# STM32WL5x_CM0P register map
File version: 1.5
CPU: CM0 r0p1, little endian, MPU, no FPU, 4 interrupt priority bits
Registers are 32-bit, read-write, reset 0x0 unless marked. A register's access mark holds for its fields unless they carry their own. Offsets are from the block's base; [hi:lo] are bit positions; {n}, {i} and the like mark numbered series.

## PWR — Power control
Base 0x58000400
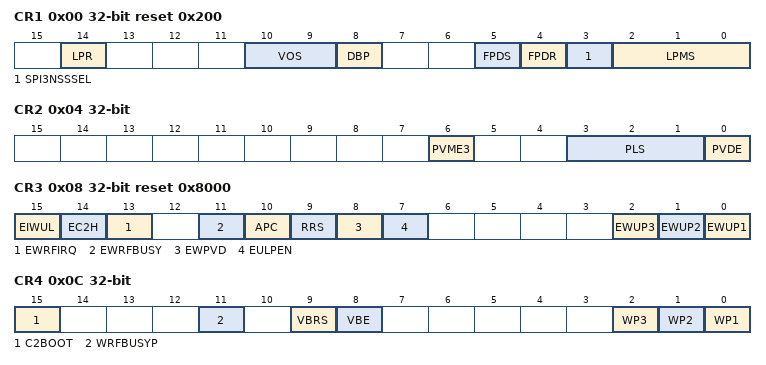
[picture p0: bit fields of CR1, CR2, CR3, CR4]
0x00 CR1 reset 0x200 — Power control register 1
  [14] LPR — Low-power run
  [10:9] VOS — Voltage scaling range selection
  [8] DBP — Disable backup domain write protection
  [5] FPDS — Flash memory power down mode during LPSleep for CPU1
  [4] FPDR — Flash memory power down mode during LPRun for CPU1
  [3] SPI3NSSSEL — SPI3 NSS source select
  [2:0] LPMS — Low-power mode selection for CPU1
0x04 CR2 — Power control register 2
  [6] PVME3 — Peripheral voltage monitoring 3 enable: VDDA vs. 1.62V
  [3:1] PLS — Power voltage detector level selection.
  [0] PVDE — Power voltage detector enable
0x08 CR3 reset 0x8000 — Power control register 3
  [15] EIWUL — Enable internal wakeup line for CPU1
  [14] EC2H — nable CPU2 Hold interrupt for CPU1
  [13] EWRFIRQ — akeup for CPU1
  [11] EWRFBUSY — Enable Radio BUSY Wakeup from Standby for CPU1
  [10] APC — Apply pull-up and pull-down configuration from CPU1
  [9] RRS — SRAM2 retention in Standby mode
  [8] EWPVD — Enable wakeup PVD for CPU1
  [7] EULPEN — Ultra-low-power enable
  [2] EWUP3 — Enable Wakeup pin WKUP3 for CPU1
  [1] EWUP2 — Enable Wakeup pin WKUP2 for CPU1
  [0] EWUP1 — Enable Wakeup pin WKUP1 for CPU1
0x0C CR4 — Power control register 4
  [15] C2BOOT — oot CPU2 after reset or wakeup from Stop or Standby modes.
  [11] WRFBUSYP — Wakeup Radio BUSY polarity
  [9] VBRS — VBAT battery charging resistor selection
  [8] VBE — VBAT battery charging enable
  [2] WP3 — Wakeup pin WKUP3 polarity
  [1] WP2 — Wakeup pin WKUP2 polarity
  [0] WP1 — Wakeup pin WKUP1 polarity
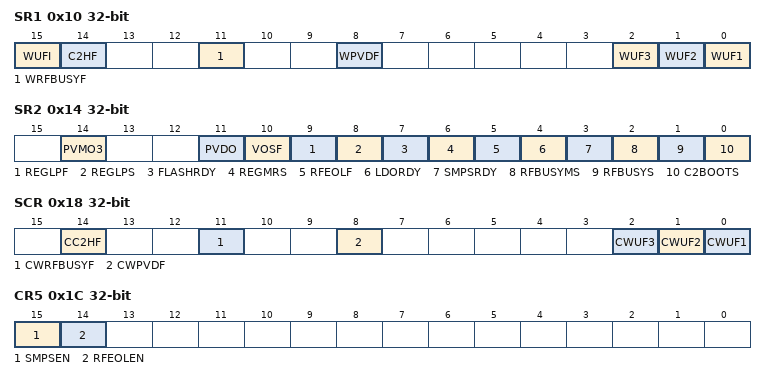
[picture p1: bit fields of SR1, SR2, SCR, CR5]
0x10 SR1 ro — Power status register 1
  [15] WUFI — Internal wakeup interrupt flag
  [14] C2HF — PU2 Hold interrupt flag
  [11] WRFBUSYF — Radio BUSY wakeup flag
  [8] WPVDF — Wakeup PVD flag
  [2] WUF3 — Wakeup flag 3
  [1] WUF2 — Wakeup flag 2
  [0] WUF1 — Wakeup flag 1
0x14 SR2 ro — Power status register 2
  [14] PVMO3 — Peripheral voltage monitoring output: VDDA vs. 1.62 V
  [11] PVDO — Power voltage detector output
  [10] VOSF — Voltage scaling flag
  [9] REGLPF — regulator1 low power flag
  [8] REGLPS — regulator1 started
  [7] FLASHRDY — Flash ready
  [6] REGMRS — regulator2 low power flag
  [5] RFEOLF — Radio end of life flag
  [4] LDORDY — LDO ready flag
  [3] SMPSRDY — SMPS ready flag
  [2] RFBUSYMS — Radio BUSY masked signal status
  [1] RFBUSYS — Radio BUSY signal status
  [0] C2BOOTS — PU2 boot/wakeup request source information
0x18 SCR wo — Power status clear register
  [14] CC2HF — lear CPU2 Hold interrupt flag
  [11] CWRFBUSYF — Clear wakeup Radio BUSY flag
  [8] CWPVDF — Clear wakeup PVD interrupt flag
  [2] CWUF3 — Clear wakeup flag 3
  [1] CWUF2 — Clear wakeup flag 2
  [0] CWUF1 — Clear wakeup flag 1
0x1C CR5 — Power control register 5
  [15] SMPSEN — Enable SMPS Step Down converter SMPS mode enabled.
  [14] RFEOLEN — Enable Radio End Of Life detector enabled
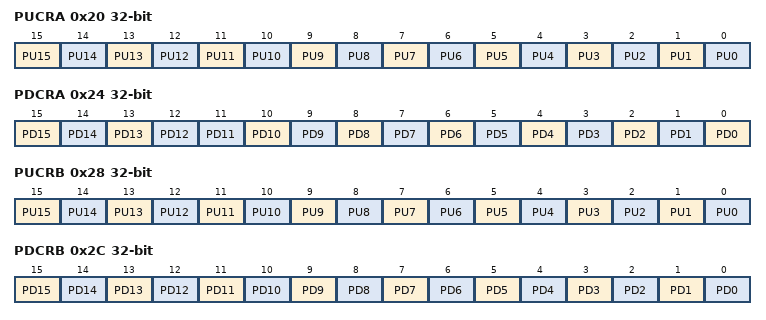
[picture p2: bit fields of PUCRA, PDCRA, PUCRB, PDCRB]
0x20 PUCRA — Power Port A pull-up control register
  [15] PU15 — Port PA15 pull-up
  [14] PU14
  [13] PU13 — Port PA[y] pull-up bit y (y=0 to 13)
  [n] PU{n} (n=0..12)
0x24 PDCRA — Power Port A pull-down control register
  [15] PD15
  [14] PD14 — ull-down
  [13] PD13
  [12] PD12 — Port PA[y] pull-down (y=0 to 12)
  [n] PD{n} (n=0..11)
0x28 PUCRB — Power Port B pull-up control register
  [15] PU15 — Port PB[y] pull-up (y=0 to 15)
  [n] PU{n} (n=0..14)
0x2C PDCRB — Power Port B pull-down control register
  [15] PD15 — Port PB[y] pull-down (y=5 to 15)
  [n] PD{n} (n=4..14)
  [3] PD3 — Port PB[y] pull-down (y=0 to 3)
  [2] PD2
  [1] PD1
  [0] PD0
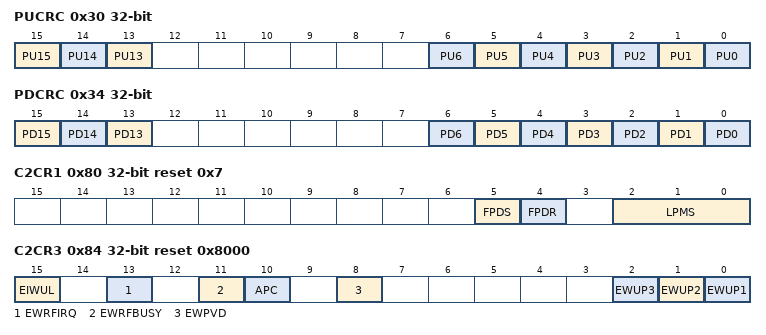
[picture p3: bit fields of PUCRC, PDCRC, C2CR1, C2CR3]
0x30 PUCRC — Power Port C pull-up control register
  [15] PU15 — Port PC[y] pull-up (y=13 to 15)
  [14] PU14
  [13] PU13
  [n] PU{n} (n=0..6)
0x34 PDCRC — Power Port C pull-down control register
  [15] PD15 — Port PC[y] pull-down (y=13 to 15)
  [14] PD14
  [13] PD13
  [n] PD{n} (n=0..6)
0x58 PUCRH — Power Port H pull-up control register
  [3] PU3 — ull-up
0x5C PDCRH — Power Port H pull-down control register
  [3] PD3 — ull-down
0x80 C2CR1 reset 0x7 — Power CPU2 control register 1 [dual core device only]
  [5] FPDS — Flash memory power down mode during LPSleep for CPU2
  [4] FPDR — Flash memory power down mode during LPRun for CPU2
  [2:0] LPMS — Low-power mode selection for CPU2
0x84 C2CR3 reset 0x8000 — Power CPU2 control register 3 [dual core device only]
  [15] EIWUL — Enable internal wakeup line for CPU2
  [13] EWRFIRQ — akeup for CPU2
  [11] EWRFBUSY
  [10] APC — Apply pull-up and pull-down configuration for CPU2
  [8] EWPVD — Enable wakeup PVD for CPU2
  [2] EWUP3 — Enable Wakeup pin WKUP3 for CPU2
  [1] EWUP2 — Enable Wakeup pin WKUP2 for CPU2
  [0] EWUP1 — Enable Wakeup pin WKUP1 for CPU2
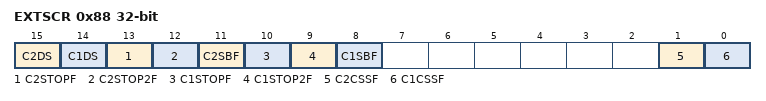
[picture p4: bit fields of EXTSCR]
0x88 EXTSCR access per field — Power extended status and status clear register
  [15] C2DS ro — PU2 deepsleep mode
  [14] C1DS ro — CPU1 deepsleep mode
  [13] C2STOPF ro — ystem Stop0, 1 flag for CPU2. (All core states retained)
  [12] C2STOP2F ro — ystem Stop2 flag for CPU2. (partial core states retained)
  [11] C2SBF ro — ystem Standby flag for CPU2. (no core states retained)
  [10] C1STOPF ro — System Stop0, 1 flag for CPU1. (All core states retained)
  [9] C1STOP2F ro — System Stop2 flag for CPU1. (partial core states retained)
  [8] C1SBF ro — System Standby flag for CPU1. (no core states retained)
  [1] C2CSSF wo — lear CPU2 Stop Standby flags
  [0] C1CSSF wo — Clear CPU1 Stop Standby flags
0x8C SECCFGR reset 0x8000 — Power security configuration register [dual core device only]
  [15] C2ILAITEN — CPU2 illegal access interrupt wakeup enable
0x90 SPI3CR reset 0x8000 — Power SPI3 control register
  [15] SPI3NSS — SPI3 NSS control
0x94 RSSCR wo — RSS configuration register [dual core device only]
  [0] RSSADIS — RSS boot region access disable
0x98 RSSCMDR — RSS Command register [dual core device only]
  [7:0] RSSCMD — RSS command
0x9C RSSSWDBGR — RSS Software debug register [dual core device only]
  [0] RSSSWDBGEN — Enable debug during RSS code execution when boot in CM0+ RSS/SFI mode.
0xA0 RSSTK1ADISR wo — RSS TK1 access register [non user] [dual core device only]
  [0] RSSTK1ADIS — RSS TK1 key access disable
0xA4 RSSTK1R0 ro — RSS TK1 key register 0 [non user] [dual core device only]
  [31:0] RSSTK1 — Secret RSS TK1 key bits 31-0
0xA8 RSSTK1R1 ro — RSS TK1 key register 1 [non user] [dual core device only]
  [31:0] RSSTK1 — Secret RSS TK1 key bits 63-32
0xAC RSSTK1R2 ro — RSS TK1 key register 2 [non user] [dual core device only]
  [31:0] RSSTK1 — Secret RSS TK1 key bits 95-94
0xB0 RSSTK1R3 ro — RSS TK1 key register 3 [non user] [dual core device only]
  [31:0] RSSTK1 — Secret RSS TK1 key bits 127-96
0xB4 RSSTK2ADISR wo — RSS TK2 access register [non user] [dual core device only]
  [0] RSSTK2ADIS — RSS TK1 key access disable
0xB8 RSSTK2R0 ro — RSS TK2 key register 0 [non user] [dual core device only]
  [31:0] RSSTK2 — Secret RSS TK2 key bits 31-0
0xBC RSSTK2R1 ro — RSS TK2 key register 1 [non user] [dual core device only]
  [31:0] RSSTK2 — Secret RSS TK2 key bits 63-32
0xC0 RSSTK2R2 ro — RSS TK2 key register 2 [non user] [dual core device only]
  [31:0] RSSTK2 — Secret RSS TK2 key bits 95-94
{0xB8+4i} RSSTK2R{i} ro (i=3..7) — RSS TK2 key register {i} [non user] [dual core device only]
  [31:0] RSSTK2 — Secret RSS TK2 key bits {32i+31}-{32i}
